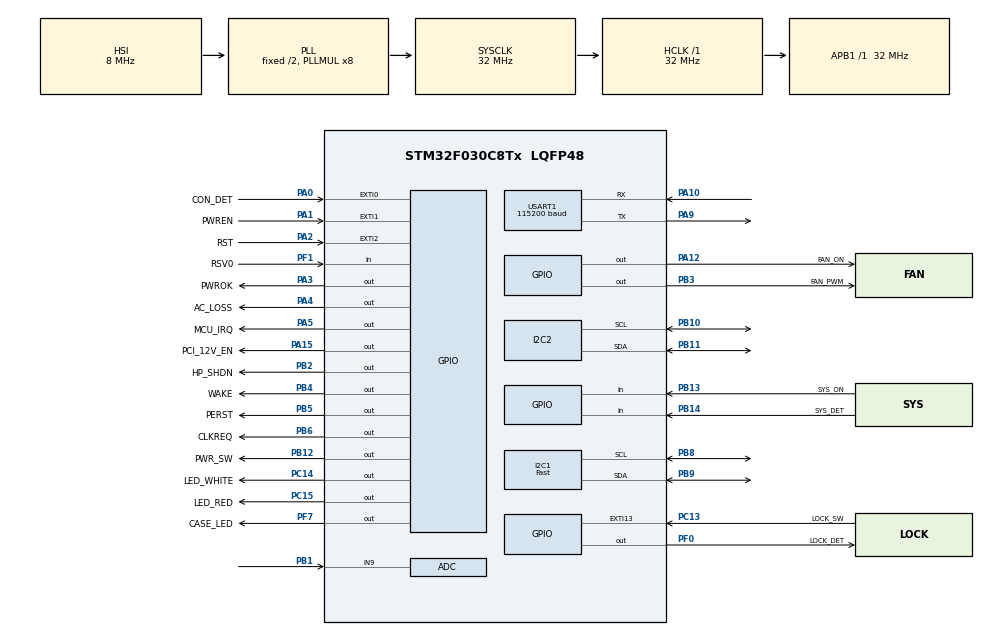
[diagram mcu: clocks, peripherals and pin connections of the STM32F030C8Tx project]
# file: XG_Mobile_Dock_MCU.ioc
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Dma.ADC.0.Direction=DMA_PERIPH_TO_MEMORY
Dma.ADC.0.Instance=DMA1_Channel1
Dma.ADC.0.MemDataAlignment=DMA_MDATAALIGN_HALFWORD
Dma.ADC.0.MemInc=DMA_MINC_ENABLE
Dma.ADC.0.Mode=DMA_NORMAL
Dma.ADC.0.PeriphDataAlignment=DMA_PDATAALIGN_HALFWORD
Dma.ADC.0.PeriphInc=DMA_PINC_DISABLE
Dma.ADC.0.Priority=DMA_PRIORITY_LOW
Dma.Request0=ADC
I2C1.I2C_Speed_Mode=I2C_Fast
I2C1.NoStretchMode=I2C_NOSTRETCH_DISABLE
I2C1.OwnAddress=115
I2C1.Timing=0x0000020B
I2C2.Timing=0x00707CBB
Mcu.Family=STM32F0
Mcu.Name=STM32F030C8Tx
Mcu.Package=LQFP48
NVIC.ADC1_IRQn=true\:0\:0\:false\:false\:true\:true\:true\:true
NVIC.DMA1_Channel1_IRQn=true\:0\:0\:false\:false\:true\:false\:true\:true
NVIC.EXTI0_1_IRQn=true\:0\:0\:false\:false\:true\:true\:true\:true
NVIC.EXTI2_3_IRQn=true\:0\:0\:false\:false\:true\:true\:true\:true
NVIC.EXTI4_15_IRQn=true\:0\:0\:false\:false\:true\:true\:true\:true
NVIC.I2C1_IRQn=true\:0\:0\:false\:false\:true\:true\:true\:true
NVIC.TIM1_BRK_UP_TRG_COM_IRQn=true\:0\:0\:false\:false\:true\:true\:true\:true
NVIC.TIM1_CC_IRQn=true\:0\:0\:false\:false\:true\:true\:true\:true
NVIC.TIM3_IRQn=true\:0\:0\:false\:false\:true\:true\:true\:true
NVIC.TIM6_IRQn=true\:0\:0\:false\:false\:true\:true\:true\:true
PA0.GPIO_Label=CON_DET
PA0.GPIO_ModeDefaultEXTI=GPIO_MODE_IT_RISING_FALLING
PA0.GPIO_PuPd=GPIO_PULLUP
PA0.Signal=GPXTI0
PA1.GPIO_Label=PWREN
PA1.GPIO_ModeDefaultEXTI=GPIO_MODE_IT_RISING_FALLING
PA1.GPIO_PuPd=GPIO_PULLUP
PA1.Signal=GPXTI1
PA10.Mode=Asynchronous
PA10.Signal=USART1_RX
PA12.GPIO_Label=FAN_ON
PA12.PinState=GPIO_PIN_RESET
PA12.Signal=GPIO_Output
PA13.Mode=Serial_Wire
PA13.Signal=SYS_SWDIO
PA14.Mode=Serial_Wire
PA14.Signal=SYS_SWCLK
PA15.GPIO_Label=PCI_12V_EN
PA15.GPIO_ModeDefaultOutputPP=GPIO_MODE_OUTPUT_OD
PA15.GPIO_PuPd=GPIO_NOPULL
PA15.PinState=GPIO_PIN_RESET
PA15.Signal=GPIO_Output
PA2.GPIO_Label=RST
PA2.GPIO_ModeDefaultEXTI=GPIO_MODE_IT_RISING_FALLING
PA2.GPIO_PuPd=GPIO_PULLUP
PA2.Signal=GPXTI2
PA3.GPIO_Label=PWROK
PA3.GPIO_ModeDefaultOutputPP=GPIO_MODE_OUTPUT_PP
PA3.GPIO_PuPd=GPIO_NOPULL
PA3.PinState=GPIO_PIN_RESET
PA3.Signal=GPIO_Output
PA4.GPIO_Label=AC_LOSS
PA4.GPIO_ModeDefaultOutputPP=GPIO_MODE_OUTPUT_PP
PA4.GPIO_PuPd=GPIO_PULLDOWN
PA4.PinState=GPIO_PIN_RESET
PA4.Signal=GPIO_Output
PA5.GPIO_Label=MCU_IRQ
PA5.GPIO_ModeDefaultOutputPP=GPIO_MODE_OUTPUT_OD
PA5.GPIO_PuPd=GPIO_PULLUP
PA5.PinState=GPIO_PIN_SET
PA5.Signal=GPIO_Output
PA9.Mode=Asynchronous
PA9.Signal=USART1_TX
PB1.Mode=IN9
PB1.Signal=ADC_IN9
PB10.Mode=I2C
PB10.Signal=I2C2_SCL
PB11.Mode=I2C
PB11.Signal=I2C2_SDA
PB12.GPIO_Label=PWR_SW
PB12.GPIO_ModeDefaultOutputPP=GPIO_MODE_OUTPUT_OD
PB12.GPIO_PuPd=GPIO_NOPULL
PB12.PinState=GPIO_PIN_SET
PB12.Signal=GPIO_Output
PB13.GPIO_Label=SYS_ON
PB13.GPIO_PuPd=GPIO_PULLDOWN
PB13.Signal=GPIO_Input
PB14.GPIO_Label=SYS_DET
PB14.GPIO_PuPd=GPIO_PULLUP
PB14.Signal=GPIO_Input
PB2.GPIO_Label=HP_SHDN
PB2.PinState=GPIO_PIN_SET
PB2.Signal=GPIO_Output
PB3.GPIO_Label=FAN_PWM
PB3.GPIO_Speed=GPIO_SPEED_FREQ_HIGH
PB3.PinState=GPIO_PIN_RESET
PB3.Signal=GPIO_Output
PB4.GPIO_Label=WAKE
PB4.GPIO_ModeDefaultOutputPP=GPIO_MODE_OUTPUT_OD
PB4.GPIO_PuPd=GPIO_PULLUP
PB4.PinState=GPIO_PIN_SET
PB4.Signal=GPIO_Output
PB5.GPIO_Label=PERST
PB5.GPIO_ModeDefaultOutputPP=GPIO_MODE_OUTPUT_OD
PB5.GPIO_PuPd=GPIO_PULLUP
PB5.PinState=GPIO_PIN_SET
PB5.Signal=GPIO_Output
PB6.GPIO_Label=CLKREQ
PB6.GPIO_ModeDefaultOutputPP=GPIO_MODE_OUTPUT_OD
PB6.GPIO_PuPd=GPIO_PULLUP
PB6.PinState=GPIO_PIN_SET
PB6.Signal=GPIO_Output
PB8.Mode=I2C
PB8.Signal=I2C1_SCL
PB9.Mode=I2C
PB9.Signal=I2C1_SDA
PC13.GPIO_Label=LOCK_SW
PC13.GPIO_ModeDefaultEXTI=GPIO_MODE_IT_RISING_FALLING
PC13.GPIO_PuPd=GPIO_PULLUP
PC13.Signal=GPXTI13
PC14-OSC32_IN.GPIO_Label=LED_WHITE
PC14-OSC32_IN.GPIO_ModeDefaultOutputPP=GPIO_MODE_OUTPUT_OD
PC14-OSC32_IN.GPIO_PuPd=GPIO_NOPULL
PC14-OSC32_IN.PinState=GPIO_PIN_SET
PC14-OSC32_IN.Signal=GPIO_Output
PC15-OSC32_OUT.GPIO_Label=LED_RED
PC15-OSC32_OUT.GPIO_ModeDefaultOutputPP=GPIO_MODE_OUTPUT_OD
PC15-OSC32_OUT.GPIO_PuPd=GPIO_NOPULL
PC15-OSC32_OUT.PinState=GPIO_PIN_SET
PC15-OSC32_OUT.Signal=GPIO_Output
PF0-OSC_IN.GPIO_Label=LOCK_DET
PF0-OSC_IN.Signal=GPIO_Output
PF1-OSC_OUT.GPIO_Label=RSV0
PF1-OSC_OUT.Signal=GPIO_Input
PF7.GPIO_Label=CASE_LED
PF7.GPIO_ModeDefaultOutputPP=GPIO_MODE_OUTPUT_OD
PF7.GPIO_PuPd=GPIO_NOPULL
PF7.PinState=GPIO_PIN_SET
PF7.Signal=GPIO_Output
ProjectManager.HeapSize=0x200
ProjectManager.StackSize=0x400
ProjectManager.TargetToolchain=Makefile
RCC.AHBFreq_Value=32000000
RCC.APB1Freq_Value=32000000
RCC.APB1TimFreq_Value=32000000
RCC.HCLKFreq_Value=32000000
RCC.PLLMUL=RCC_PLL_MUL8
RCC.SYSCLKFreq_VALUE=32000000
RCC.SYSCLKSource=RCC_SYSCLKSOURCE_PLLCLK
TIM1.AutoReloadPreload=TIM_AUTORELOAD_PRELOAD_DISABLE
TIM1.Channel-PWM\ Generation1\ No\ Output=TIM_CHANNEL_1
TIM1.Period=99
TIM1.Prescaler=11
TIM3.Period=1
TIM3.Prescaler=2000
TIM6.Period=49999
TIM6.Prescaler=63
USART1.BaudRate=115200
USART1.VirtualMode-Asynchronous=VM_ASYNC
VP_ADC_Vref_Input.Mode=IN-Vrefint
VP_TIM1_VS_ClockSourceINT.Mode=Internal
VP_TIM1_VS_no_output1.Mode=PWM Generation1 No Output
VP_TIM3_VS_ClockSourceINT.Mode=Internal
VP_TIM6_VS_ClockSourceINT.Mode=Enable_Timer
board=custom

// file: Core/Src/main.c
/* USER CODE BEGIN Header */
/**
  ******************************************************************************
  * @file           : main.c
  * @brief          : Main program body
  ******************************************************************************
  * @attention
  *
  * Copyright (c) 2024 STMicroelectronics.
  * All rights reserved.
  *
  * This software is licensed under terms that can be found in the LICENSE file
  * in the root directory of this software component.
  * If no LICENSE file comes with this software, it is provided AS-IS.
  *
  ******************************************************************************
  */
/* USER CODE END Header */
#include "main.h"

ADC_HandleTypeDef hadc;
DMA_HandleTypeDef hdma_adc;

I2C_HandleTypeDef hi2c1;
I2C_HandleTypeDef hi2c2;

TIM_HandleTypeDef htim1;
TIM_HandleTypeDef htim3;
TIM_HandleTypeDef htim6;

UART_HandleTypeDef huart1;

void SystemClock_Config(void);
static void MX_GPIO_Init(void);
static void MX_DMA_Init(void);
static void MX_I2C2_Init(void);
static void MX_USART1_UART_Init(void);
static void MX_TIM1_Init(void);
static void MX_I2C1_Init(void);
static void MX_ADC_Init(void);
static void MX_TIM3_Init(void);
static void MX_TIM6_Init(void);

/* USER CODE BEGIN 0 */
extern void main_fsm_iteration(void);
extern void fans_update(void);

/* USER CODE END 0 */

int main(void)
{

  /* MCU Configuration--------------------------------------------------------*/

  /* Reset of all peripherals, Initializes the Flash interface and the Systick. */
  HAL_Init();

  /* Configure the system clock */
  SystemClock_Config();

  /* Initialize all configured peripherals */
  MX_GPIO_Init();
  MX_DMA_Init();
  MX_I2C2_Init();
  MX_USART1_UART_Init();
  MX_TIM1_Init();
  MX_I2C1_Init();
  MX_ADC_Init();
  MX_TIM3_Init();
  MX_TIM6_Init();

  /* Infinite loop */
  while (1)
  {

    /* USER CODE BEGIN 3 */
    main_fsm_iteration();
    fans_update();
  }
  /* USER CODE END 3 */
}

void SystemClock_Config(void)
{
  RCC_OscInitTypeDef RCC_OscInitStruct = {0};
  RCC_ClkInitTypeDef RCC_ClkInitStruct = {0};
  RCC_PeriphCLKInitTypeDef PeriphClkInit = {0};

  /** Initializes the RCC Oscillators according to the specified parameters
  * in the RCC_OscInitTypeDef structure.
  */
  RCC_OscInitStruct.OscillatorType = RCC_OSCILLATORTYPE_HSI|RCC_OSCILLATORTYPE_HSI14;
  RCC_OscInitStruct.HSIState = RCC_HSI_ON;
  RCC_OscInitStruct.HSI14State = RCC_HSI14_ON;
  RCC_OscInitStruct.HSICalibrationValue = RCC_HSICALIBRATION_DEFAULT;
  RCC_OscInitStruct.HSI14CalibrationValue = 16;
  RCC_OscInitStruct.PLL.PLLState = RCC_PLL_ON;
  RCC_OscInitStruct.PLL.PLLSource = RCC_PLLSOURCE_HSI;
  RCC_OscInitStruct.PLL.PLLMUL = RCC_PLL_MUL8;
  RCC_OscInitStruct.PLL.PREDIV = RCC_PREDIV_DIV1;
  if (HAL_RCC_OscConfig(&RCC_OscInitStruct) != HAL_OK)
  {
    Error_Handler();
  }

  /** Initializes the CPU, AHB and APB buses clocks
  */
  RCC_ClkInitStruct.ClockType = RCC_CLOCKTYPE_HCLK|RCC_CLOCKTYPE_SYSCLK
                              |RCC_CLOCKTYPE_PCLK1;
  RCC_ClkInitStruct.SYSCLKSource = RCC_SYSCLKSOURCE_PLLCLK;
  RCC_ClkInitStruct.AHBCLKDivider = RCC_SYSCLK_DIV1;
  RCC_ClkInitStruct.APB1CLKDivider = RCC_HCLK_DIV1;

  if (HAL_RCC_ClockConfig(&RCC_ClkInitStruct, FLASH_LATENCY_1) != HAL_OK)
  {
    Error_Handler();
  }
  PeriphClkInit.PeriphClockSelection = RCC_PERIPHCLK_USART1|RCC_PERIPHCLK_I2C1;
  PeriphClkInit.Usart1ClockSelection = RCC_USART1CLKSOURCE_PCLK1;
  PeriphClkInit.I2c1ClockSelection = RCC_I2C1CLKSOURCE_HSI;
  if (HAL_RCCEx_PeriphCLKConfig(&PeriphClkInit) != HAL_OK)
  {
    Error_Handler();
  }
}

static void MX_ADC_Init(void)
{

  ADC_ChannelConfTypeDef sConfig = {0};

  /** Configure the global features of the ADC (Clock, Resolution, Data Alignment and number of conversion)
  */
  hadc.Instance = ADC1;
  hadc.Init.ClockPrescaler = ADC_CLOCK_ASYNC_DIV1;
  hadc.Init.Resolution = ADC_RESOLUTION_12B;
  hadc.Init.DataAlign = ADC_DATAALIGN_RIGHT;
  hadc.Init.ScanConvMode = ADC_SCAN_DIRECTION_FORWARD;
  hadc.Init.EOCSelection = ADC_EOC_SINGLE_CONV;
  hadc.Init.LowPowerAutoWait = DISABLE;
  hadc.Init.LowPowerAutoPowerOff = DISABLE;
  hadc.Init.ContinuousConvMode = DISABLE;
  hadc.Init.DiscontinuousConvMode = DISABLE;
  hadc.Init.ExternalTrigConv = ADC_SOFTWARE_START;
  hadc.Init.ExternalTrigConvEdge = ADC_EXTERNALTRIGCONVEDGE_NONE;
  hadc.Init.DMAContinuousRequests = DISABLE;
  hadc.Init.Overrun = ADC_OVR_DATA_PRESERVED;
  if (HAL_ADC_Init(&hadc) != HAL_OK)
  {
    Error_Handler();
  }

  /** Configure for the selected ADC regular channel to be converted.
  */
  sConfig.Channel = ADC_CHANNEL_9;
  sConfig.Rank = ADC_RANK_CHANNEL_NUMBER;
  sConfig.SamplingTime = ADC_SAMPLETIME_1CYCLE_5;
  if (HAL_ADC_ConfigChannel(&hadc, &sConfig) != HAL_OK)
  {
    Error_Handler();
  }

  /** Configure for the selected ADC regular channel to be converted.
  */
  sConfig.Channel = ADC_CHANNEL_VREFINT;
  if (HAL_ADC_ConfigChannel(&hadc, &sConfig) != HAL_OK)
  {
    Error_Handler();
  }

}

static void MX_I2C1_Init(void)
{

  hi2c1.Instance = I2C1;
  hi2c1.Init.Timing = 0x0000020B;
  hi2c1.Init.OwnAddress1 = 230;
  hi2c1.Init.AddressingMode = I2C_ADDRESSINGMODE_7BIT;
  hi2c1.Init.DualAddressMode = I2C_DUALADDRESS_DISABLE;
  hi2c1.Init.OwnAddress2 = 0;
  hi2c1.Init.OwnAddress2Masks = I2C_OA2_NOMASK;
  hi2c1.Init.GeneralCallMode = I2C_GENERALCALL_DISABLE;
  hi2c1.Init.NoStretchMode = I2C_NOSTRETCH_DISABLE;
  if (HAL_I2C_Init(&hi2c1) != HAL_OK)
  {
    Error_Handler();
  }

  /** Configure Analogue filter
  */
  if (HAL_I2CEx_ConfigAnalogFilter(&hi2c1, I2C_ANALOGFILTER_ENABLE) != HAL_OK)
  {
    Error_Handler();
  }

  /** Configure Digital filter
  */
  if (HAL_I2CEx_ConfigDigitalFilter(&hi2c1, 0) != HAL_OK)
  {
    Error_Handler();
  }

}

static void MX_I2C2_Init(void)
{

  hi2c2.Instance = I2C2;
  hi2c2.Init.Timing = 0x00707CBB;
  hi2c2.Init.OwnAddress1 = 0;
  hi2c2.Init.AddressingMode = I2C_ADDRESSINGMODE_7BIT;
  hi2c2.Init.DualAddressMode = I2C_DUALADDRESS_DISABLE;
  hi2c2.Init.OwnAddress2 = 0;
  hi2c2.Init.OwnAddress2Masks = I2C_OA2_NOMASK;
  hi2c2.Init.GeneralCallMode = I2C_GENERALCALL_DISABLE;
  hi2c2.Init.NoStretchMode = I2C_NOSTRETCH_DISABLE;
  if (HAL_I2C_Init(&hi2c2) != HAL_OK)
  {
    Error_Handler();
  }

  /** Configure Analogue filter
  */
  if (HAL_I2CEx_ConfigAnalogFilter(&hi2c2, I2C_ANALOGFILTER_ENABLE) != HAL_OK)
  {
    Error_Handler();
  }

  /** Configure Digital filter
  */
  if (HAL_I2CEx_ConfigDigitalFilter(&hi2c2, 0) != HAL_OK)
  {
    Error_Handler();
  }

}

static void MX_TIM1_Init(void)
{

  TIM_ClockConfigTypeDef sClockSourceConfig = {0};
  TIM_MasterConfigTypeDef sMasterConfig = {0};
  TIM_OC_InitTypeDef sConfigOC = {0};
  TIM_BreakDeadTimeConfigTypeDef sBreakDeadTimeConfig = {0};

  htim1.Instance = TIM1;
  htim1.Init.Prescaler = 11;
  htim1.Init.CounterMode = TIM_COUNTERMODE_UP;
  htim1.Init.Period = 99;
  htim1.Init.ClockDivision = TIM_CLOCKDIVISION_DIV1;
  htim1.Init.RepetitionCounter = 0;
  htim1.Init.AutoReloadPreload = TIM_AUTORELOAD_PRELOAD_DISABLE;
  if (HAL_TIM_Base_Init(&htim1) != HAL_OK)
  {
    Error_Handler();
  }
  sClockSourceConfig.ClockSource = TIM_CLOCKSOURCE_INTERNAL;
  if (HAL_TIM_ConfigClockSource(&htim1, &sClockSourceConfig) != HAL_OK)
  {
    Error_Handler();
  }
  if (HAL_TIM_PWM_Init(&htim1) != HAL_OK)
  {
    Error_Handler();
  }
  sMasterConfig.MasterOutputTrigger = TIM_TRGO_RESET;
  sMasterConfig.MasterSlaveMode = TIM_MASTERSLAVEMODE_DISABLE;
  if (HAL_TIMEx_MasterConfigSynchronization(&htim1, &sMasterConfig) != HAL_OK)
  {
    Error_Handler();
  }
  sConfigOC.OCMode = TIM_OCMODE_PWM1;
  sConfigOC.Pulse = 0;
  sConfigOC.OCPolarity = TIM_OCPOLARITY_HIGH;
  sConfigOC.OCNPolarity = TIM_OCNPOLARITY_HIGH;
  sConfigOC.OCFastMode = TIM_OCFAST_DISABLE;
  sConfigOC.OCIdleState = TIM_OCIDLESTATE_RESET;
  sConfigOC.OCNIdleState = TIM_OCNIDLESTATE_RESET;
  if (HAL_TIM_PWM_ConfigChannel(&htim1, &sConfigOC, TIM_CHANNEL_1) != HAL_OK)
  {
    Error_Handler();
  }
  sBreakDeadTimeConfig.OffStateRunMode = TIM_OSSR_DISABLE;
  sBreakDeadTimeConfig.OffStateIDLEMode = TIM_OSSI_DISABLE;
  sBreakDeadTimeConfig.LockLevel = TIM_LOCKLEVEL_OFF;
  sBreakDeadTimeConfig.DeadTime = 0;
  sBreakDeadTimeConfig.BreakState = TIM_BREAK_DISABLE;
  sBreakDeadTimeConfig.BreakPolarity = TIM_BREAKPOLARITY_HIGH;
  sBreakDeadTimeConfig.AutomaticOutput = TIM_AUTOMATICOUTPUT_DISABLE;
  if (HAL_TIMEx_ConfigBreakDeadTime(&htim1, &sBreakDeadTimeConfig) != HAL_OK)
  {
    Error_Handler();
  }

}

static void MX_TIM3_Init(void)
{

  TIM_ClockConfigTypeDef sClockSourceConfig = {0};
  TIM_MasterConfigTypeDef sMasterConfig = {0};

  htim3.Instance = TIM3;
  htim3.Init.Prescaler = 2000;
  htim3.Init.CounterMode = TIM_COUNTERMODE_UP;
  htim3.Init.Period = 1;
  htim3.Init.ClockDivision = TIM_CLOCKDIVISION_DIV1;
  htim3.Init.AutoReloadPreload = TIM_AUTORELOAD_PRELOAD_DISABLE;
  if (HAL_TIM_Base_Init(&htim3) != HAL_OK)
  {
    Error_Handler();
  }
  sClockSourceConfig.ClockSource = TIM_CLOCKSOURCE_INTERNAL;
  if (HAL_TIM_ConfigClockSource(&htim3, &sClockSourceConfig) != HAL_OK)
  {
    Error_Handler();
  }
  sMasterConfig.MasterOutputTrigger = TIM_TRGO_RESET;
  sMasterConfig.MasterSlaveMode = TIM_MASTERSLAVEMODE_DISABLE;
  if (HAL_TIMEx_MasterConfigSynchronization(&htim3, &sMasterConfig) != HAL_OK)
  {
    Error_Handler();
  }

}

static void MX_TIM6_Init(void)
{

  htim6.Instance = TIM6;
  htim6.Init.Prescaler = 63;
  htim6.Init.CounterMode = TIM_COUNTERMODE_UP;
  htim6.Init.Period = 49999;
  htim6.Init.AutoReloadPreload = TIM_AUTORELOAD_PRELOAD_DISABLE;
  if (HAL_TIM_Base_Init(&htim6) != HAL_OK)
  {
    Error_Handler();
  }

}

static void MX_USART1_UART_Init(void)
{

  huart1.Instance = USART1;
  huart1.Init.BaudRate = 115200;
  huart1.Init.WordLength = UART_WORDLENGTH_8B;
  huart1.Init.StopBits = UART_STOPBITS_1;
  huart1.Init.Parity = UART_PARITY_NONE;
  huart1.Init.Mode = UART_MODE_TX_RX;
  huart1.Init.HwFlowCtl = UART_HWCONTROL_NONE;
  huart1.Init.OverSampling = UART_OVERSAMPLING_16;
  huart1.Init.OneBitSampling = UART_ONE_BIT_SAMPLE_DISABLE;
  huart1.AdvancedInit.AdvFeatureInit = UART_ADVFEATURE_NO_INIT;
  if (HAL_UART_Init(&huart1) != HAL_OK)
  {
    Error_Handler();
  }

}

static void MX_DMA_Init(void)
{

  /* DMA controller clock enable */
  __HAL_RCC_DMA1_CLK_ENABLE();

  /* DMA interrupt init */
  /* DMA1_Channel1_IRQn interrupt configuration */
  HAL_NVIC_SetPriority(DMA1_Channel1_IRQn, 0, 0);
  HAL_NVIC_EnableIRQ(DMA1_Channel1_IRQn);

}

static void MX_GPIO_Init(void)
{
  GPIO_InitTypeDef GPIO_InitStruct = {0};

  /* GPIO Ports Clock Enable */
  __HAL_RCC_GPIOC_CLK_ENABLE();
  __HAL_RCC_GPIOF_CLK_ENABLE();
  __HAL_RCC_GPIOA_CLK_ENABLE();
  __HAL_RCC_GPIOB_CLK_ENABLE();

  /*Configure GPIO pin Output Level */
  HAL_GPIO_WritePin(GPIOC, LED_WHITE_Pin|LED_RED_Pin, GPIO_PIN_SET);

  /*Configure GPIO pin Output Level */
  HAL_GPIO_WritePin(LOCK_DET_GPIO_Port, LOCK_DET_Pin, GPIO_PIN_RESET);

  /*Configure GPIO pin Output Level */
  HAL_GPIO_WritePin(GPIOA, PWROK_Pin|AC_LOSS_Pin|FAN_ON_Pin|PCI_12V_EN_Pin, GPIO_PIN_RESET);

  /*Configure GPIO pin Output Level */
  HAL_GPIO_WritePin(MCU_IRQ_GPIO_Port, MCU_IRQ_Pin, GPIO_PIN_SET);

  /*Configure GPIO pin Output Level */
  HAL_GPIO_WritePin(GPIOB, HP_SHDN_Pin|PWR_SW_Pin|WAKE_Pin|PERST_Pin
                          |CLKREQ_Pin, GPIO_PIN_SET);

  /*Configure GPIO pin Output Level */
  HAL_GPIO_WritePin(CASE_LED_GPIO_Port, CASE_LED_Pin, GPIO_PIN_SET);

  /*Configure GPIO pin Output Level */
  HAL_GPIO_WritePin(FAN_PWM_GPIO_Port, FAN_PWM_Pin, GPIO_PIN_RESET);

  /*Configure GPIO pin : LOCK_SW_Pin */
  GPIO_InitStruct.Pin = LOCK_SW_Pin;
  GPIO_InitStruct.Mode = GPIO_MODE_IT_RISING_FALLING;
  GPIO_InitStruct.Pull = GPIO_PULLUP;
  HAL_GPIO_Init(LOCK_SW_GPIO_Port, &GPIO_InitStruct);

  /*Configure GPIO pins : LED_WHITE_Pin LED_RED_Pin */
  GPIO_InitStruct.Pin = LED_WHITE_Pin|LED_RED_Pin;
  GPIO_InitStruct.Mode = GPIO_MODE_OUTPUT_OD;
  GPIO_InitStruct.Pull = GPIO_NOPULL;
  GPIO_InitStruct.Speed = GPIO_SPEED_FREQ_LOW;
  HAL_GPIO_Init(GPIOC, &GPIO_InitStruct);

  /*Configure GPIO pin : LOCK_DET_Pin */
  GPIO_InitStruct.Pin = LOCK_DET_Pin;
  GPIO_InitStruct.Mode = GPIO_MODE_OUTPUT_PP;
  GPIO_InitStruct.Pull = GPIO_NOPULL;
  GPIO_InitStruct.Speed = GPIO_SPEED_FREQ_LOW;
  HAL_GPIO_Init(LOCK_DET_GPIO_Port, &GPIO_InitStruct);

  /*Configure GPIO pin : RSV0_Pin */
  GPIO_InitStruct.Pin = RSV0_Pin;
  GPIO_InitStruct.Mode = GPIO_MODE_INPUT;
  GPIO_InitStruct.Pull = GPIO_NOPULL;
  HAL_GPIO_Init(RSV0_GPIO_Port, &GPIO_InitStruct);

  /*Configure GPIO pins : CON_DET_Pin PWREN_Pin RST_Pin */
  GPIO_InitStruct.Pin = CON_DET_Pin|PWREN_Pin|RST_Pin;
  GPIO_InitStruct.Mode = GPIO_MODE_IT_RISING_FALLING;
  GPIO_InitStruct.Pull = GPIO_PULLUP;
  HAL_GPIO_Init(GPIOA, &GPIO_InitStruct);

  /*Configure GPIO pins : PWROK_Pin FAN_ON_Pin */
  GPIO_InitStruct.Pin = PWROK_Pin|FAN_ON_Pin;
  GPIO_InitStruct.Mode = GPIO_MODE_OUTPUT_PP;
  GPIO_InitStruct.Pull = GPIO_NOPULL;
  GPIO_InitStruct.Speed = GPIO_SPEED_FREQ_LOW;
  HAL_GPIO_Init(GPIOA, &GPIO_InitStruct);

  /*Configure GPIO pin : AC_LOSS_Pin */
  GPIO_InitStruct.Pin = AC_LOSS_Pin;
  GPIO_InitStruct.Mode = GPIO_MODE_OUTPUT_PP;
  GPIO_InitStruct.Pull = GPIO_PULLDOWN;
  GPIO_InitStruct.Speed = GPIO_SPEED_FREQ_LOW;
  HAL_GPIO_Init(AC_LOSS_GPIO_Port, &GPIO_InitStruct);

  /*Configure GPIO pin : MCU_IRQ_Pin */
  GPIO_InitStruct.Pin = MCU_IRQ_Pin;
  GPIO_InitStruct.Mode = GPIO_MODE_OUTPUT_OD;
  GPIO_InitStruct.Pull = GPIO_PULLUP;
  GPIO_InitStruct.Speed = GPIO_SPEED_FREQ_LOW;
  HAL_GPIO_Init(MCU_IRQ_GPIO_Port, &GPIO_InitStruct);

  /*Configure GPIO pin : HP_SHDN_Pin */
  GPIO_InitStruct.Pin = HP_SHDN_Pin;
  GPIO_InitStruct.Mode = GPIO_MODE_OUTPUT_PP;
  GPIO_InitStruct.Pull = GPIO_NOPULL;
  GPIO_InitStruct.Speed = GPIO_SPEED_FREQ_LOW;
  HAL_GPIO_Init(HP_SHDN_GPIO_Port, &GPIO_InitStruct);

  /*Configure GPIO pin : PWR_SW_Pin */
  GPIO_InitStruct.Pin = PWR_SW_Pin;
  GPIO_InitStruct.Mode = GPIO_MODE_OUTPUT_OD;
  GPIO_InitStruct.Pull = GPIO_NOPULL;
  GPIO_InitStruct.Speed = GPIO_SPEED_FREQ_LOW;
  HAL_GPIO_Init(PWR_SW_GPIO_Port, &GPIO_InitStruct);

  /*Configure GPIO pin : SYS_ON_Pin */
  GPIO_InitStruct.Pin = SYS_ON_Pin;
  GPIO_InitStruct.Mode = GPIO_MODE_INPUT;
  GPIO_InitStruct.Pull = GPIO_PULLDOWN;
  HAL_GPIO_Init(SYS_ON_GPIO_Port, &GPIO_InitStruct);

  /*Configure GPIO pin : SYS_DET_Pin */
  GPIO_InitStruct.Pin = SYS_DET_Pin;
  GPIO_InitStruct.Mode = GPIO_MODE_INPUT;
  GPIO_InitStruct.Pull = GPIO_PULLUP;
  HAL_GPIO_Init(SYS_DET_GPIO_Port, &GPIO_InitStruct);

  /*Configure GPIO pin : CASE_LED_Pin */
  GPIO_InitStruct.Pin = CASE_LED_Pin;
  GPIO_InitStruct.Mode = GPIO_MODE_OUTPUT_OD;
  GPIO_InitStruct.Pull = GPIO_NOPULL;
  GPIO_InitStruct.Speed = GPIO_SPEED_FREQ_LOW;
  HAL_GPIO_Init(CASE_LED_GPIO_Port, &GPIO_InitStruct);

  /*Configure GPIO pin : PCI_12V_EN_Pin */
  GPIO_InitStruct.Pin = PCI_12V_EN_Pin;
  GPIO_InitStruct.Mode = GPIO_MODE_OUTPUT_OD;
  GPIO_InitStruct.Pull = GPIO_NOPULL;
  GPIO_InitStruct.Speed = GPIO_SPEED_FREQ_LOW;
  HAL_GPIO_Init(PCI_12V_EN_GPIO_Port, &GPIO_InitStruct);

  /*Configure GPIO pin : FAN_PWM_Pin */
  GPIO_InitStruct.Pin = FAN_PWM_Pin;
  GPIO_InitStruct.Mode = GPIO_MODE_OUTPUT_PP;
  GPIO_InitStruct.Pull = GPIO_NOPULL;
  GPIO_InitStruct.Speed = GPIO_SPEED_FREQ_HIGH;
  HAL_GPIO_Init(FAN_PWM_GPIO_Port, &GPIO_InitStruct);

  /*Configure GPIO pins : WAKE_Pin PERST_Pin CLKREQ_Pin */
  GPIO_InitStruct.Pin = WAKE_Pin|PERST_Pin|CLKREQ_Pin;
  GPIO_InitStruct.Mode = GPIO_MODE_OUTPUT_OD;
  GPIO_InitStruct.Pull = GPIO_PULLUP;
  GPIO_InitStruct.Speed = GPIO_SPEED_FREQ_LOW;
  HAL_GPIO_Init(GPIOB, &GPIO_InitStruct);

  /* EXTI interrupt init*/
  HAL_NVIC_SetPriority(EXTI0_1_IRQn, 0, 0);
  HAL_NVIC_EnableIRQ(EXTI0_1_IRQn);

  HAL_NVIC_SetPriority(EXTI2_3_IRQn, 0, 0);
  HAL_NVIC_EnableIRQ(EXTI2_3_IRQn);

  HAL_NVIC_SetPriority(EXTI4_15_IRQn, 0, 0);
  HAL_NVIC_EnableIRQ(EXTI4_15_IRQn);

}

void Error_Handler(void)
{
  __disable_irq();
  while (1)
  {
  }
}
